# SYS__System_Module_6 register map
Vendor: Texas Instruments
Peripheral module from a debugger description file (folder msp430).
Registers are 16-bit, access not given, no defined reset value unless marked. A register's access mark holds for its fields unless they carry their own. Offsets are as the file gives them; lines under a group give offsets from that group; [hi:lo] are bit positions; {n}, {i} and the like mark numbered series; 'fields as' and 'values as' point back to an identical list; <NAME> marks a mode.

## SYS_System_Module
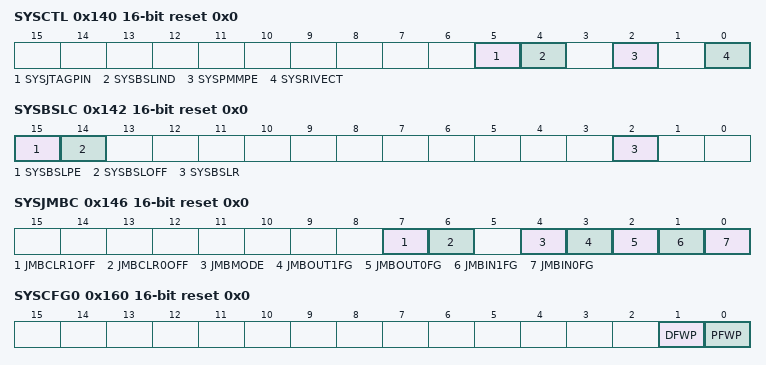
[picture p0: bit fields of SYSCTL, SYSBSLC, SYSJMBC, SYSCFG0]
0x140 SYSCTL rw reset 0x0 — System control
  [5] SYSJTAGPIN — SYS - Dedicated JTAG pins enabled
  [4] SYSBSLIND — SYS - TCK/RST indication detected
  [2] SYSPMMPE — SYS - PMM access protect
  [0] SYSRIVECT — SYS - RAM based interrupt vectors
0x142 SYSBSLC rw reset 0x0 — Boot strap configuration area
  [15] SYSBSLPE — SYS - BSL Memory protection enabled
  [14] SYSBSLOFF — SYS - BSL Memory disabled
  [2] SYSBSLR — SYS - RAM assigned to BSL
0x146 SYSJMBC rw reset 0x0 — JTAG mailbox control
  [7] JMBCLR1OFF — SYS - Incoming JTAG Mailbox 1 Flag auto-clear disalbe
  [6] JMBCLR0OFF — SYS - Incoming JTAG Mailbox 0 Flag auto-clear disalbe
  [4] JMBMODE — SYS - JMB 16/32 Bit Mode
  [3] JMBOUT1FG — SYS - Outgoing JTAG Mailbox 1 Flag
  [2] JMBOUT0FG — SYS - Outgoing JTAG Mailbox 0 Flag
  [1] JMBIN1FG — SYS - Incoming JTAG Mailbox 1 Flag
  [0] JMBIN0FG — SYS - Incoming JTAG Mailbox 0 Flag
0x148 SYSJMBI0 — JTAG mailbox input 0
0x14A SYSJMBI1 — JTAG mailbox input 1
0x14C SYSJMBO0 — JTAG mailbox output 0
0x14E SYSJMBO1 — JTAG mailbox output 1
0x158 SYSBERRIV — Bus Error vector generator
0x15A SYSUNIV — User NMI vector generator
0x15C SYSSNIV — System NMI vector generator
0x15E SYSRSTIV — Reset vector generator
0x160 SYSCFG0 rw reset 0x0 — System Configuration 0
  [1] DFWP — Data FRAM Write Protection
  [0] PFWP — Program FRAM Write Protection
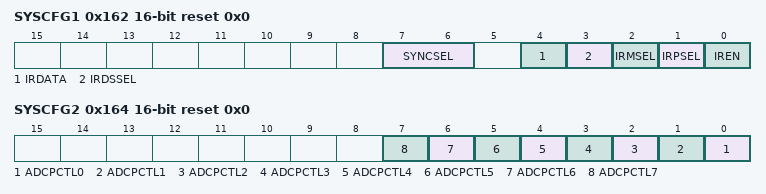
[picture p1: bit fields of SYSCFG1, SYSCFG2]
0x162 SYSCFG1 rw reset 0x0 — System Configuration 1
  [7:6] SYNCSEL — Captivate conversion triggered source select Bit: 0
    0=Captivate conversion triggered source select: External; 1=Captivate conversion triggered source select: ADC; 2=Captivate conversion triggered source select: Comparator; 3=Captivate conversion triggered source select: Res; 3=Captivate conversion triggered source select: Res
  [4] IRDATA — Infrared enable
  [3] IRDSSEL — Infrared data source select
  [2] IRMSEL — Infrared mode select
  [1] IRPSEL — Infrared polarity select
  [0] IREN — Infrared enable
0x164 SYSCFG2 rw reset 0x0 — System Configuration 2
  [n] ADCPCTL{n} (n=0..7) — ADC input A{n} pin select
